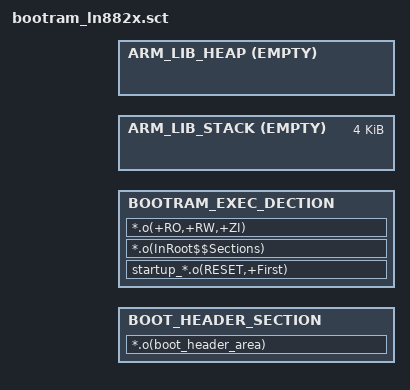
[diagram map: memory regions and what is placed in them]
#! armcc -E

#include "..\..\..\..\mcu\ln88xx\mem_map_ln882x.h"

LOAD_BOOTRAM  BOOTRAM_BASE  36864  {
    BOOT_HEADER_SECTION +0{
        *.o(boot_header_area);
    }

    BOOTRAM_EXEC_DECTION +0 ALIGN 0x100 ((RETENTION_MEM_BASE-BOOTRAM_BASE+RETENTION_MEM_SIZE-1024)-167744-0x1000){
        startup_*.o(RESET,+First);
        *.o(InRoot$$Sections);
        *.o(+RO,+RW,+ZI);
    }
	
	ARM_LIB_STACK +0 EMPTY 0x1000 { }
	
    ARM_LIB_HEAP +0 EMPTY (RETENTION_MEM_BASE+RETENTION_MEM_SIZE-1024)-ImageLimit(BOOTRAM_EXEC_DECTION)-0x1000
    {
    }
}
